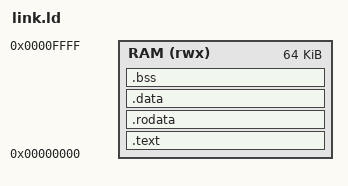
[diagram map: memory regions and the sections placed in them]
/* Everything in the 64 KB RAM at 0x0; reset pc = 0 = _start. */
OUTPUT_ARCH(riscv)
ENTRY(_start)

MEMORY { RAM (rwx) : ORIGIN = 0x00000000, LENGTH = 64K }

SECTIONS
{
  .text : {
    KEEP(*(.text.init))
    *(.text .text.*)
  } > RAM
  .rodata : { *(.rodata .rodata.* .srodata .srodata.*) } > RAM
  .data : ALIGN(4) { *(.data .data.* .sdata .sdata.*) } > RAM
  .bss (NOLOAD) : ALIGN(4) {
    __bss_start = .;
    *(.sbss .sbss.* .bss .bss.* COMMON)
    . = ALIGN(4);
    __bss_end = .;
  } > RAM
  __stack_top = ORIGIN(RAM) + LENGTH(RAM);
  /DISCARD/ : { *(.comment .riscv.attributes .note .note.*) }
}
